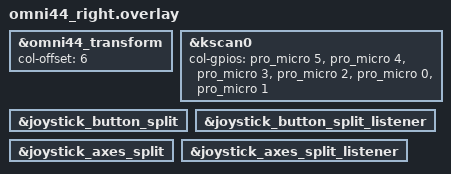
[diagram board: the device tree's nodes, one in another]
#include "omni44.dtsi"

&omni44_transform {
    col-offset = <6>;
};

&kscan0 {
    // The right PCB is mirrored, so reverse its local columns for the layout.
    col-gpios
        = <&pro_micro 5 GPIO_ACTIVE_HIGH>
        , <&pro_micro 4 GPIO_ACTIVE_HIGH>
        , <&pro_micro 3 GPIO_ACTIVE_HIGH>
        , <&pro_micro 2 GPIO_ACTIVE_HIGH>
        , <&pro_micro 0 GPIO_ACTIVE_HIGH>
        , <&pro_micro 1 GPIO_ACTIVE_HIGH>
        ;
};

&joystick_button_split {
    status = "okay";
};

&joystick_button_split_listener {
    status = "okay";
};

&joystick_axes_split {
    status = "okay";
};

&joystick_axes_split_listener {
    status = "okay";
};
